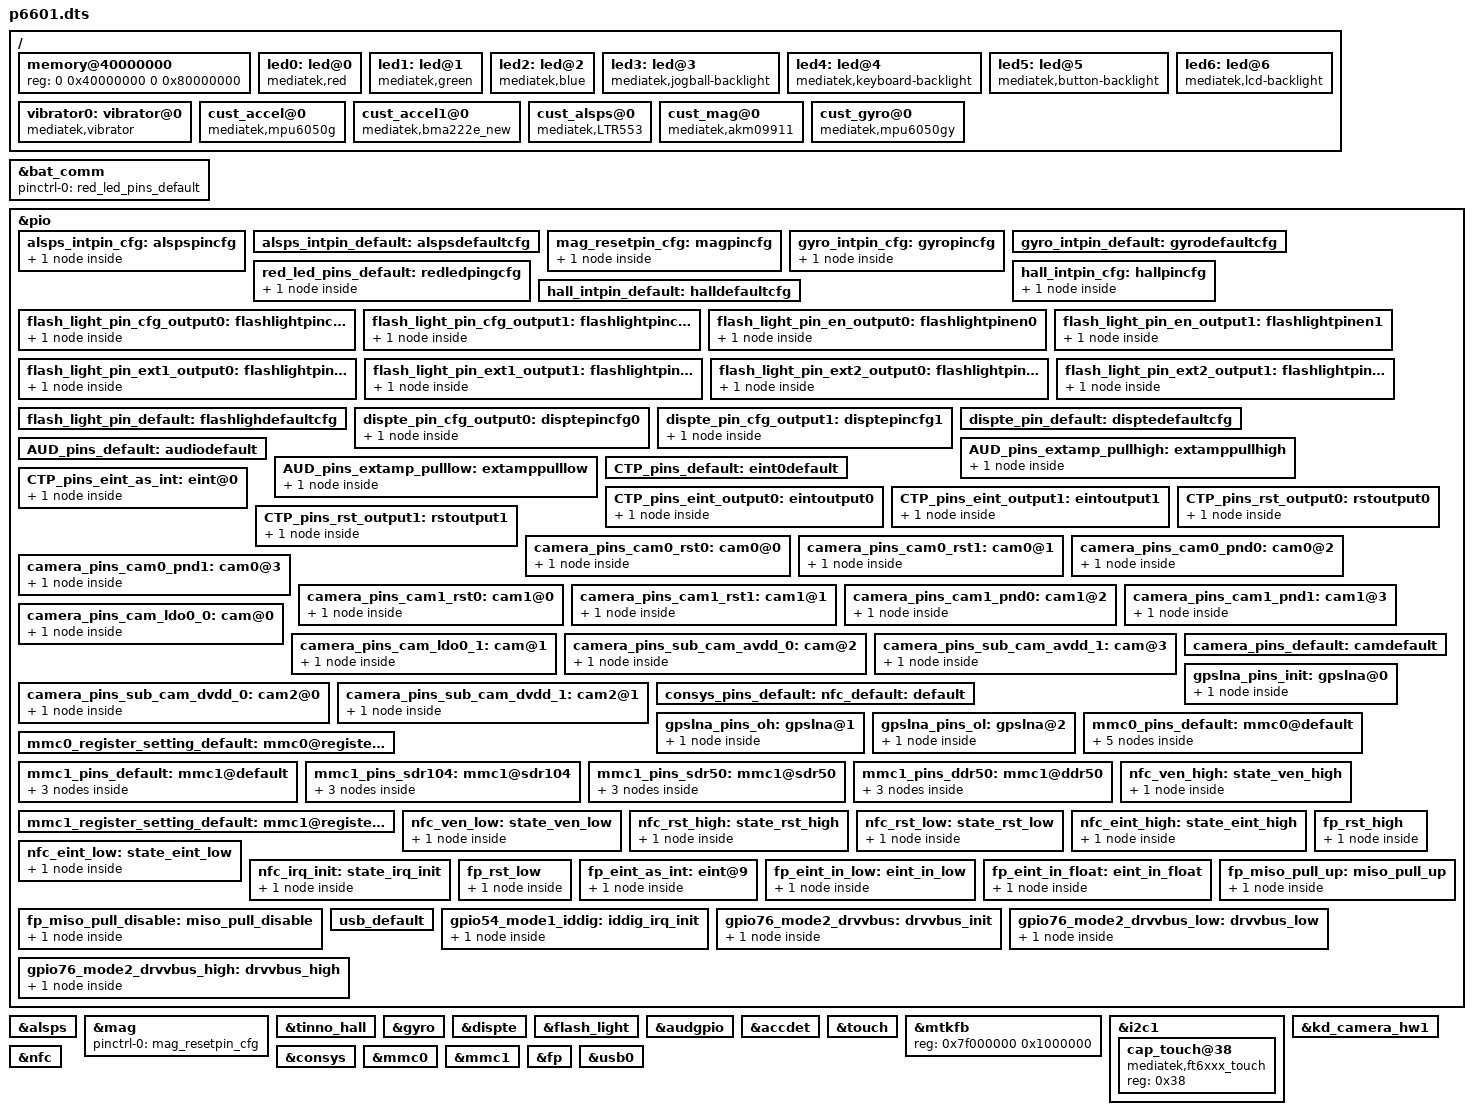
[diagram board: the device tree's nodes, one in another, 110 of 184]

/dts-v1/;

#include "mt6735.dtsi"
#include "cust.dtsi"

/ {
	memory@40000000 {
		device_type = "memory";
		reg = <0 0x40000000 0 0x80000000>;
	};

	led0:led@0 {
		compatible = "mediatek,red";
		led_mode = <3>;
		data = <2>;
		pwm_config = <0 0 0 0 0>;
	};
	led1:led@1 {
		compatible = "mediatek,green";
		led_mode = <3>;
		data = <1>;
		pwm_config = <0 0 0 0 0>;
	};
	led2:led@2 {
		compatible = "mediatek,blue";
		led_mode = <0>;
		data = <1>;
		pwm_config = <0 0 0 0 0>;
	};
	led3:led@3 {
		compatible = "mediatek,jogball-backlight";
		led_mode = <0>;
		data = <1>;
		pwm_config = <0 0 0 0 0>;
	};
	led4:led@4 {
		compatible = "mediatek,keyboard-backlight";
		led_mode = <0>;
		data = <1>;
		pwm_config = <0 0 0 0 0>;
	};
	led5:led@5 {
		compatible = "mediatek,button-backlight";
		led_mode = <0>;
		data = <1>;
		pwm_config = <0 0 0 0 0>;
	};
	led6:led@6 {
		compatible = "mediatek,lcd-backlight";
		led_mode = <5>;
		data = <1>;
		pwm_config = <0 0 0 0 0>;
	};
	vibrator0:vibrator@0 {
		compatible = "mediatek,vibrator";
		vib_timer = <25>;
		vib_limit = <9>;
		vib_vol= <5>;
	};
 /* sensor standardization */
		cust_accel@0 {
		compatible				= "mediatek,mpu6050g";
		i2c_num				= <2>;
		i2c_addr				= <0x68 0 0 0>;
		direction				= <6>;
		power_id				= <0xffff>;
		power_vol				= <0>;
		firlen					= <0>;
		is_batch_supported			= <0>;
		};
                //BEGIN <bma222e> <DATA20160309> <bma222e config> limi.zhang
		cust_accel1@0 {
		compatible				= "mediatek,bma222e_new";
		i2c_num				= <2>;
		i2c_addr				= <0x18 0 0 0>;
		direction				= <7>;
		power_id				= <0xffff>;
		power_vol				= <0>;
		firlen					= <0>;
		is_batch_supported			= <0>;
		};
                //END <bma222e> <DATA20160309> <bma222e config> limi.zhang
		cust_alsps@0 {
		compatible				= "mediatek,LTR553";
		i2c_num					= <2>;
		i2c_addr				= <0x23 0 0 0>;
		polling_mode_ps			= <0>;
		polling_mode_als		= <1>;
		power_id				= <0xffff>;
		power_vol				= <0>;
/* Total has 15 level*/
		als_level	= <2 16 32 64 613 1400 2238 3253 4401 5606 6844 8196 65535 65535 65535>;
/*  Total has 16 range*/
		als_value	= <18 50 95 190 1000 1700 1920 2900 5745 8500 10243 10243 10243 10243 10243 10243>;
		ps_threshold_high		=  <0x167>;
		ps_threshold_low		=  <0x74>;
		is_batch_supported_ps	= <0>;
		is_batch_supported_als	= <0>;
		};
		cust_mag@0 {
		compatible				= "mediatek,akm09911";
		i2c_num				= <2>;
		i2c_addr				= <0x0C 0 0 0>;
		direction				= <6>;
		power_id				= <0xffff>;
		power_vol				= <0>;
		is_batch_supported	= <0>;
		};

		cust_gyro@0 {
		compatible				= "mediatek,mpu6050gy";
		i2c_num				= <2>;
		i2c_addr				= <0x69 0 0 0>;
		direction				= <6>;
		power_id				= <0xffff>;
		power_vol				= <0>;
		firlen					= <0>;
		is_batch_supported	= <0>;
		};
};

&bat_comm {
	pinctrl-names = "default";
	pinctrl-0 = <&red_led_pins_default>;
};
/* sensor gpio standization */
&pio {
	alsps_intpin_cfg: alspspincfg {

	    pins_cmd_dat {
			pins = <PINMUX_GPIO58__FUNC_GPIO58>;
			slew-rate = <0>;
			bias-pull-up = <00>;
		};
	};

	alsps_intpin_default: alspsdefaultcfg {

	};

	mag_resetpin_cfg: magpincfg {
	    pins_cmd_dat {
			pins = <PINMUX_GPIO61__FUNC_GPIO61>;
			slew-rate = <1>;
			output-high;
		};
	};

	gyro_intpin_cfg: gyropincfg {

	    pins_cmd_dat {
			pins = <PINMUX_GPIO59__FUNC_GPIO59>;
			slew-rate = <0>;
			bias-pull-down = <00>;
		};
	};

	gyro_intpin_default: gyrodefaultcfg {

	};

	red_led_pins_default: redledpingcfg{
		pins_cmd_dat {
			pins = <PINMUX_GPIO8__FUNC_GPIO8>;
			slew-rate = <1>;
			output-high;
		};
	};


};
&alsps {
	pinctrl-names = "pin_default", "pin_cfg";
	pinctrl-0 = <&alsps_intpin_default>;
	pinctrl-1 = <&alsps_intpin_cfg>;
	status = "okay";

};

&mag {
	pinctrl-names = "default";
	pinctrl-0 = <&mag_resetpin_cfg>;
	status = "okay";
};

&pio {
	hall_intpin_cfg: hallpincfg {
	    pins_cmd_dat {
			pins = <PINMUX_GPIO0__FUNC_GPIO0>;
			slew-rate = <0>;
			bias-pull-up = <00>;
		};
	};
	hall_intpin_default: halldefaultcfg {
	};

};
&tinno_hall {
	pinctrl-names = "pin_default", "pin_cfg";
	pinctrl-0 = <&hall_intpin_default>;
	pinctrl-1 = <&hall_intpin_cfg>;
	status = "okay";
};

&gyro {
	pinctrl-names = "pin_default", "pin_cfg";
	pinctrl-0 = <&gyro_intpin_default>;
	pinctrl-1 = <&gyro_intpin_cfg>;
	status = "okay";

};
/* sensor end */
&pio {
	flash_light_pin_cfg_output0: flashlightpincfg0 {
	    pins_cmd_dat {
			pins = <PINMUX_GPIO42__FUNC_GPIO42>;
			slew-rate = <1>;
			output-low;
		};
	};
	flash_light_pin_cfg_output1: flashlightpincfg1 {
	    pins_cmd_dat {
			pins = <PINMUX_GPIO42__FUNC_GPIO42>;
			slew-rate = <1>;
			output-high;
		};
	};
	flash_light_pin_en_output0: flashlightpinen0 {
	    pins_cmd_dat {
			pins = <PINMUX_GPIO43__FUNC_GPIO43>;
			slew-rate = <1>;
			output-low;
		};
	};
	flash_light_pin_en_output1: flashlightpinen1 {
	    pins_cmd_dat {
			pins = <PINMUX_GPIO43__FUNC_GPIO43>;
			slew-rate = <1>;
			output-high;
		};
	};
	flash_light_pin_ext1_output0: flashlightpinext10 {
	    pins_cmd_dat {
			pins = <PINMUX_GPIO3__FUNC_GPIO3>;
			slew-rate = <1>;
			output-low;
		};
	};
	flash_light_pin_ext1_output1: flashlightpinext11 {
	    pins_cmd_dat {
			pins = <PINMUX_GPIO3__FUNC_GPIO3>;
			slew-rate = <1>;
			output-high;
		};
	};
	flash_light_pin_ext2_output0: flashlightpinext20 {
	    pins_cmd_dat {
			pins = <PINMUX_GPIO4__FUNC_GPIO4>;
			slew-rate = <1>;
			output-low;
		};
	};
	flash_light_pin_ext2_output1: flashlightpinext21 {
	    pins_cmd_dat {
			pins = <PINMUX_GPIO4__FUNC_GPIO4>;
			slew-rate = <1>;
			output-high;
		};
	};
	flash_light_pin_default: flashlighdefaultcfg {
	};

};
/*DISPTE START*/
&pio {
	dispte_pin_cfg_output0: disptepincfg0 {
	    pins_cmd_dat {
			pins = <PINMUX_GPIO146__FUNC_GPIO146>;
			slew-rate = <1>;
			output-low;
		};
	};
	dispte_pin_cfg_output1: disptepincfg1 {
	    pins_cmd_dat {
			pins = <PINMUX_GPIO146__FUNC_GPIO146>;
			slew-rate = <1>;
			output-high;
		};
	};
	dispte_pin_default: disptedefaultcfg {
	};
};
&dispte {
	pinctrl-names = "disptepin_default", "disptepin_cfg0", "disptepin_cfg1";
	pinctrl-0 = <&dispte_pin_default>;
	pinctrl-1 = <&dispte_pin_cfg_output0>;
	pinctrl-2 = <&dispte_pin_cfg_output1>;
	status = "okay";
};
/*DISPTE END*/
&flash_light {
	pinctrl-names = "flashlightpin_default", "flashlightpin_cfg0", "flashlightpin_cfg1","flashlightpin_en0","flashlightpin_en1"
			 ,"flashlightpin_ext10","flashlightpin_ext11","flashlightpin_ext20","flashlightpin_ext21";
	pinctrl-0 = <&flash_light_pin_default>;
	pinctrl-1 = <&flash_light_pin_cfg_output0>;
	pinctrl-2 = <&flash_light_pin_cfg_output1>;
	pinctrl-3 = <&flash_light_pin_en_output0>;
	pinctrl-4 = <&flash_light_pin_en_output1>;
	pinctrl-5 = <&flash_light_pin_ext1_output0>;
	pinctrl-6 = <&flash_light_pin_ext1_output1>;
	pinctrl-7 = <&flash_light_pin_ext2_output0>;
	pinctrl-8 = <&flash_light_pin_ext2_output1>;
	status = "okay";
};
/* AUDIO GPIO standardization */
&audgpio {
	pinctrl-names = "default", "extamp-pullhigh", "extamp-pulllow";
	pinctrl-0 = <&AUD_pins_default>;

	pinctrl-1 = <&AUD_pins_extamp_pullhigh>;
	pinctrl-2 = <&AUD_pins_extamp_pulllow>;
	gpio_extspkamp = <&pio 19 0>;//yangliang add for ext pa mode-2;
	status = "okay";
};
&pio {
	AUD_pins_default: audiodefault {
	};

	AUD_pins_extamp_pullhigh: extamppullhigh {
	    pins_cmd_dat {
			pins = <PINMUX_GPIO19__FUNC_GPIO19>;/*GPIO_extamp_PIN*/
			slew-rate = <1>;
			output-high;
		};
	};
	AUD_pins_extamp_pulllow: extamppulllow {
	    pins_cmd_dat {
			pins = <PINMUX_GPIO19__FUNC_GPIO19>;/*GPIO_extamp_PIN*/
			slew-rate = <1>;
			output-low;
		};
	};
};
/* AUDIO end */
&accdet {
		accdet-mic-vol = <7>;
		//headset-mode-setting = <0x500 0x200 1 0x1F0 0x800 0x800 0x20>;//yangliang mask and add for insert hph-pop according to mtk20160418
		headset-mode-setting = <0x500 0x500 1 0x3F0 0x800 0x800 0x20>; 
		accdet-plugout-debounce = <20>;
		/*1:ACC mode, 2:low cost without in bias, 6:low cost with in bias*/
		accdet-mic-mode = <6>;
		/*0--MD_MAX--UP_MAX--DW_MAX*/
		headset-three-key-threshold = <0 80 220 500>;
		/*0--MD_MAX--VOICE_MAX--UP_MAX--DW_MAX*/
		headset-four-key-threshold = <0 58 121 192 450>;
};
&touch {
	tpd-resolution = <720 1280>;
	use-tpd-button = <0>;
	tpd-key-num = <3>;
	tpd-key-local= <139 172 158 0>;
	tpd-key-dim-local = <90 883 100 40 230 883 100 40 370 883 100 40 0 0 0 0>;
	tpd-max-touch-num = <5>;
	tpd-filter-enable = <0>;
	tpd-filter-pixel-density = <124>;
	tpd-filter-custom-prameters = <0 0 0 0 0 0 0 0 0 0 0 0>;
	tpd-filter-custom-speed = <0 0 0>;
	pinctrl-names = "default", "state_eint_as_int", "state_eint_output0", "state_eint_output1",
		"state_rst_output0", "state_rst_output1";
	pinctrl-0 = <&CTP_pins_default>;
	pinctrl-1 = <&CTP_pins_eint_as_int>;
	pinctrl-2 = <&CTP_pins_eint_output0>;
	pinctrl-3 = <&CTP_pins_eint_output1>;
	pinctrl-4 = <&CTP_pins_rst_output0>;
	pinctrl-5 = <&CTP_pins_rst_output1>;
	status = "okay";
};

&mtkfb {
	reg = <0x7f000000 0x1000000>;
};


&pio {
	CTP_pins_default: eint0default {
	};
	CTP_pins_eint_as_int: eint@0 {
		pins_cmd_dat {
			pins = <PINMUX_GPIO10__FUNC_GPIO10>;
			slew-rate = <0>;
			bias-disable;
		};
	};
	CTP_pins_eint_output0: eintoutput0 {
		pins_cmd_dat {
			pins = <PINMUX_GPIO10__FUNC_GPIO10>;
			slew-rate = <1>;
			output-low;
		};
	};
	CTP_pins_eint_output1: eintoutput1 {
		pins_cmd_dat {
			pins = <PINMUX_GPIO10__FUNC_GPIO10>;
			slew-rate = <1>;
			output-high;
		};
	};
	CTP_pins_rst_output0: rstoutput0 {
		pins_cmd_dat {
			pins = <PINMUX_GPIO62__FUNC_GPIO62>;
			slew-rate = <1>;
			output-low;
		};
	};
	CTP_pins_rst_output1: rstoutput1 {
		pins_cmd_dat {
			pins = <PINMUX_GPIO62__FUNC_GPIO62>;
			slew-rate = <1>;
			output-high;
		};
	};
};
/* TOUCH end */
&i2c1 {
	cap_touch@38 {
		compatible = "mediatek,ft6xxx_touch";
		reg = <0x38>;
		status = "okay";
	};

};
/* CAMERA GPIO standardization */
&pio {
	camera_pins_cam0_rst0: cam0@0 {
		pins_cmd_dat {
			pins = <PINMUX_GPIO44__FUNC_GPIO44>;/*GPIO_CAMERA_CMRST_PIN*/
			slew-rate = <1>; /*direction 0:in, 1:out*/
			output-low;/*direction out used only. output_low or high*/
		};
	};
	camera_pins_cam0_rst1: cam0@1 {
		pins_cmd_dat {
			pins = <PINMUX_GPIO44__FUNC_GPIO44>;/*GPIO_CAMERA_CMRST_PIN*/
			slew-rate = <1>;
			output-high;
		};
	};
	camera_pins_cam0_pnd0: cam0@2 {
		pins_cmd_dat {
			pins = <PINMUX_GPIO7__FUNC_GPIO7>;/*GPIO_CAMERA_CMPDN_PIN*/
			slew-rate = <1>;
			output-low;
		};
	};
	camera_pins_cam0_pnd1: cam0@3 {
		pins_cmd_dat {
			pins = <PINMUX_GPIO7__FUNC_GPIO7>;/*GPIO_CAMERA_CMPDN_PIN*/
			slew-rate = <1>;
			output-high;
		};
	};
	camera_pins_cam1_rst0: cam1@0 {
		pins_cmd_dat {
			pins = <PINMUX_GPIO11__FUNC_GPIO11>;/*GPIO_CAMERA_CMRST1_PIN*/
			slew-rate = <1>; /*direction 0:in, 1:out*/
			output-low;/*direction out used only. output_low or high*/
		};
	};
	camera_pins_cam1_rst1: cam1@1 {
		pins_cmd_dat {
			pins = <PINMUX_GPIO11__FUNC_GPIO11>;/*GPIO_CAMERA_CMRST1_PIN*/
			slew-rate = <1>;
			output-high;
		};
	};
	camera_pins_cam1_pnd0: cam1@2 {
		pins_cmd_dat {
			pins = <PINMUX_GPIO12__FUNC_GPIO12>;/*GPIO_CAMERA_CMPDN1_PIN*/
			slew-rate = <1>;
			output-low;
		};
	};
	camera_pins_cam1_pnd1: cam1@3 {
		pins_cmd_dat {
			pins = <PINMUX_GPIO12__FUNC_GPIO12>;/*GPIO_CAMERA_CMPDN1_PIN*/
			slew-rate = <1>;
			output-high;
		};
	};
	camera_pins_cam_ldo0_0: cam@0 {
		pins_cmd_dat {
			pins = <PINMUX_GPIO83__FUNC_GPIO83>;
			slew-rate = <1>;
			output-low;
		};
	};
	camera_pins_cam_ldo0_1: cam@1 {
		pins_cmd_dat {
			pins = <PINMUX_GPIO83__FUNC_GPIO83>;
			slew-rate = <1>;
			output-high;
		};
	};
	camera_pins_sub_cam_avdd_0: cam@2 {
		pins_cmd_dat {
			pins = <PINMUX_GPIO78__FUNC_GPIO78>;
			slew-rate = <1>;
			output-low;
		};
	};
	camera_pins_sub_cam_avdd_1: cam@3 {
		pins_cmd_dat {
			pins = <PINMUX_GPIO78__FUNC_GPIO78>;
			slew-rate = <1>;
			output-high;
		};
	};
	camera_pins_sub_cam_dvdd_0: cam2@0 {
		pins_cmd_dat {
			pins = <PINMUX_GPIO80__FUNC_GPIO80>;
			slew-rate = <1>;
			output-low;
		};
	};
	camera_pins_sub_cam_dvdd_1: cam2@1 {
		pins_cmd_dat {
			pins = <PINMUX_GPIO80__FUNC_GPIO80>;
			slew-rate = <1>;
			output-high;
		};
	};
	camera_pins_default: camdefault {

	};
};

&kd_camera_hw1 {
	pinctrl-names = "default", "cam0_rst0", "cam0_rst1", "cam0_pnd0", "cam0_pnd1",
	"cam1_rst0", "cam1_rst1", "cam1_pnd0", "cam1_pnd1",
	"cam_ldo0_0", "cam_ldo0_1","sub_cam_avdd_0","sub_cam_avdd_1","sub_cam_dvdd_0","sub_cam_dvdd_1";
	pinctrl-0 = <&camera_pins_default>;
	pinctrl-1 = <&camera_pins_cam0_rst0>;
	pinctrl-2 = <&camera_pins_cam0_rst1>;
	pinctrl-3 = <&camera_pins_cam0_pnd0>;
	pinctrl-4 = <&camera_pins_cam0_pnd1>;
	pinctrl-5 = <&camera_pins_cam1_rst0>;
	pinctrl-6 = <&camera_pins_cam1_rst1>;
	pinctrl-7 = <&camera_pins_cam1_pnd0>;
	pinctrl-8 = <&camera_pins_cam1_pnd1>;
	pinctrl-9 = <&camera_pins_cam_ldo0_0>;
	pinctrl-10 = <&camera_pins_cam_ldo0_1>;
	pinctrl-11 = <&camera_pins_sub_cam_avdd_0>;
	pinctrl-12 = <&camera_pins_sub_cam_avdd_1>;
	pinctrl-13 = <&camera_pins_sub_cam_dvdd_0>;
	pinctrl-14 = <&camera_pins_sub_cam_dvdd_1>;
	status = "okay";

};
/* CAMERA GPIO end */

/* CONSYS GPIO standardization */
&pio {
	consys_pins_default: default {

	};

	gpslna_pins_init: gpslna@0 {

	    pins_cmd_dat {
			pins = <PINMUX_GPIO79__FUNC_GPIO79>;
			slew-rate = <0>;
			bias-disable;
			output-low;
		};
	};

	gpslna_pins_oh: gpslna@1 {

	    pins_cmd_dat {
			pins = <PINMUX_GPIO79__FUNC_GPIO79>;
			slew-rate = <1>;
			output-high;
		};
	};

	gpslna_pins_ol: gpslna@2 {

	    pins_cmd_dat {
			pins = <PINMUX_GPIO79__FUNC_GPIO79>;
			slew-rate = <1>;
			output-low;
		};
	};

};

&consys {
	pinctrl-names = "default", "gps_lna_state_init", "gps_lna_state_oh", "gps_lna_state_ol";
	pinctrl-0 = <&consys_pins_default>;
	pinctrl-1 = <&gpslna_pins_init>;
	pinctrl-2 = <&gpslna_pins_oh>;
	pinctrl-3 = <&gpslna_pins_ol>;
	status = "okay";

};
/* CONSYS end */

/* mmc start */
&mmc0 {
		clk_src = /bits/ 8 <MSDC50_CLKSRC_400MHZ>;
		bus-width = <8>;
		max-frequency = <200000000>;
		cap-mmc-highspeed;
		msdc-sys-suspend;
		mmc-ddr-1_8v;
		mmc-hs200-1_8v;
		mmc-hs400-1_8v;
		non-removable;
		pinctl = <&mmc0_pins_default>;
		register_setting = <&mmc0_register_setting_default>;
		host_function = /bits/ 8 <MSDC_EMMC>;
		bootable;
		status = "okay";
};

&mmc1 {
		clk_src = /bits/ 8 <MSDC30_CLKSRC_200MHZ>;
		bus-width = <4>;
		max-frequency = <200000000>;
		msdc-sys-suspend;
		cap-sd-highspeed;
		sd-uhs-sdr12;
		sd-uhs-sdr25;
		sd-uhs-sdr50;
		sd-uhs-sdr104;
		sd-uhs-ddr50;
		pinctl = <&mmc1_pins_default>;
		pinctl_sdr104 = <&mmc1_pins_sdr104>;
		pinctl_sdr50 = <&mmc1_pins_sdr50>;
		pinctl_ddr50 = <&mmc1_pins_ddr50>;
		register_setting = <&mmc1_register_setting_default>;
		host_function = /bits/ 8 <MSDC_SD>;
		cd_level = /bits/ 8 <MSDC_CD_LOW>;
		cd-gpios = <&pio 5 0>;
		status = "okay";
};

&pio {
	mmc0_pins_default: mmc0@default {
			pins_cmd {
				drive-strength = /bits/ 8 <2>;
			};
			pins_dat {
				drive-strength = /bits/ 8 <2>;
			};
			pins_clk {
				drive-strength = /bits/ 8 <2>;
			};
			pins_rst {
				drive-strength = /bits/ 8 <2>;
			};
			pins_ds {
				drive-strength = /bits/ 8 <2>;
			};
	};

	mmc0_register_setting_default: mmc0@register_default {
		dat0rddly      = /bits/ 8 <0>;
		dat1rddly      = /bits/ 8 <0>;
		dat2rddly      = /bits/ 8 <0>;
		dat3rddly      = /bits/ 8 <0>;
		dat4rddly      = /bits/ 8 <0>;
		dat5rddly      = /bits/ 8 <0>;
		dat6rddly      = /bits/ 8 <0>;
		dat7rddly      = /bits/ 8 <0>;
		datwrddly      = /bits/ 8 <0>;
		cmdrrddly      = /bits/ 8 <0>;
		cmdrddly       = /bits/ 8 <0>;
		cmd_edge = /bits/ 8 <MSDC_SMPL_FALLING>;
		rdata_edge = /bits/ 8 <MSDC_SMPL_FALLING>;
		wdata_edge = /bits/ 8 <MSDC_SMPL_FALLING>;

		ett-hs200-cells = <12>;
		ett-hs200-default = <OFFSET_MSDC_PATCH_BIT0	MSDC_PB0_INT_DAT_LATCH_CK_SEL 0x0
			OFFSET_MSDC_PATCH_BIT0	MSDC_PB0_CKGEN_MSDC_DLY_SEL   0x0
			OFFSET_MSDC_PATCH_BIT1	MSDC_PB1_CMD_RSP_TA_CNTR      0x1
			OFFSET_MSDC_IOCON		MSDC_IOCON_RSPL               0x0
			OFFSET_MSDC_PAD_TUNE0	MSDC_PAD_TUNE0_CMDRDLY        0x7
			OFFSET_MSDC_PAD_TUNE0	MSDC_PAD_TUNE0_CMDRRDLY       0xb
			OFFSET_MSDC_PATCH_BIT1		MSDC_PB1_WRDAT_CRCS_TA_CNTR   0x1
			OFFSET_MSDC_PAD_TUNE0	MSDC_PAD_TUNE0_DATWRDLY       0xb
			OFFSET_MSDC_IOCON			MSDC_IOCON_W_D0SPL            0x0
			OFFSET_MSDC_DAT_RDDLY0		MSDC_DAT_RDDLY0_D0            0x7
			OFFSET_MSDC_PAD_TUNE0	MSDC_PAD_TUNE0_DATRRDLY       0x9
			OFFSET_MSDC_IOCON		MSDC_IOCON_R_D_SMPL           0x0>;

		ett-hs400-cells = <8>;
		ett-hs400-default = <OFFSET_MSDC_PATCH_BIT0	MSDC_PB0_INT_DAT_LATCH_CK_SEL	0x0
			OFFSET_MSDC_PATCH_BIT0		MSDC_PB0_CKGEN_MSDC_DLY_SEL		0x0
			OFFSET_EMMC50_PAD_DS_TUNE	MSDC_EMMC50_PAD_DS_TUNE_DLY1	0x2
			OFFSET_EMMC50_PAD_DS_TUNE	MSDC_EMMC50_PAD_DS_TUNE_DLY3	0x10
			OFFSET_MSDC_PATCH_BIT1			MSDC_PB1_CMD_RSP_TA_CNTR	0x1
			OFFSET_MSDC_IOCON		MSDC_IOCON_RSPL				0x0
			OFFSET_MSDC_PAD_TUNE0			MSDC_PAD_TUNE0_CMDRDLY		0x6
			OFFSET_MSDC_PAD_TUNE0		MSDC_PAD_TUNE0_CMDRRDLY		0x6>;
	};

	mmc1_pins_default: mmc1@default {
			pins_cmd {
				drive-strength = /bits/ 8 <3>;
			};
			pins_dat {
				drive-strength = /bits/ 8 <3>;
			};
			pins_clk {
				drive-strength = /bits/ 8 <3>;
			};
	};

	mmc1_pins_sdr104: mmc1@sdr104 {
			pins_cmd {
				drive-strength = /bits/ 8 <2>;
			};
			pins_dat {
				drive-strength = /bits/ 8 <2>;
			};
			pins_clk {
				drive-strength = /bits/ 8 <3>;
			};
	};

	mmc1_pins_sdr50: mmc1@sdr50 {
			pins_cmd {
				drive-strength = /bits/ 8 <2>;
			};
			pins_dat {
				drive-strength = /bits/ 8 <2>;
			};
			pins_clk {
				drive-strength = /bits/ 8 <3>;
			};
	};

	mmc1_pins_ddr50: mmc1@ddr50 {
			pins_cmd {
				drive-strength = /bits/ 8 <2>;
			};
			pins_dat {
				drive-strength = /bits/ 8 <2>;
			};
			pins_clk {
				drive-strength = /bits/ 8 <3>;
			};
	};

	mmc1_register_setting_default: mmc1@register_default {
				dat0rddly      = /bits/ 8 <0>;
				dat1rddly      = /bits/ 8 <0>;
				dat2rddly      = /bits/ 8 <0>;
				dat3rddly      = /bits/ 8 <0>;
				datwrddly      = /bits/ 8 <0>;
				cmdrrddly      = /bits/ 8 <0>;
				cmdrddly       = /bits/ 8 <0>;
				cmd_edge = /bits/ 8 <MSDC_SMPL_FALLING>;
				rdata_edge = /bits/ 8 <MSDC_SMPL_FALLING>;
				wdata_edge = /bits/ 8 <MSDC_SMPL_FALLING>;
	};
};
/* mmc end */

/* NFC GPIO standardization */
&pio {
	nfc_default: default {

	};

	nfc_ven_high: state_ven_high {
		pins_cmd_dat {
			pins = <PINMUX_GPIO4__FUNC_GPIO4>;
			slew-rate = <1>;
			output-high;
		};
	};

	nfc_ven_low: state_ven_low {
		pins_cmd_dat {
			pins = <PINMUX_GPIO4__FUNC_GPIO4>;
			slew-rate = <1>;
			output-low;
		};
	};

	nfc_rst_high: state_rst_high {
		pins_cmd_dat {
			pins = <PINMUX_GPIO3__FUNC_GPIO3>;
			slew-rate = <1>;
			output-high;
		};
	};

	nfc_rst_low: state_rst_low {
		pins_cmd_dat {
			pins = <PINMUX_GPIO3__FUNC_GPIO3>;
			slew-rate = <1>;
			output-low;
		};
	};

	nfc_eint_high: state_eint_high {
		pins_cmd_dat {
			pins = <PINMUX_GPIO1__FUNC_GPIO1>;
			slew-rate = <1>;
			output-high;
		};
	};

	nfc_eint_low: state_eint_low {
		pins_cmd_dat {
			pins = <PINMUX_GPIO1__FUNC_GPIO1>;
			slew-rate = <1>;
			output-low;
		};
	};

	nfc_irq_init: state_irq_init {
		pins_cmd_dat {
			pins = <PINMUX_GPIO2__FUNC_GPIO2>;
			slew-rate = <0>;
			bias-pull-down = <00>;
		};
	};
};

&nfc {
	pinctrl-names = "default", "ven_high", "ven_low", "rst_high", "rst_low", "eint_high", "eint_low", "irq_init";
	pinctrl-0 = <&nfc_default>;
	pinctrl-1 = <&nfc_ven_high>;
	pinctrl-2 = <&nfc_ven_low>;
	pinctrl-3 = <&nfc_rst_high>;
	pinctrl-4 = <&nfc_rst_low>;
	pinctrl-5 = <&nfc_eint_high>;
	pinctrl-6 = <&nfc_eint_low>;
	pinctrl-7 = <&nfc_irq_init>;
	status = "okay";
};
/* NFC end */

/* Fingerprint GPIO standardization */
&pio {
	fp_default: default {
	};

	fp_rst_high: fp_rst_high {
		pins_cmd_dat {
			pins = <PINMUX_GPIO20__FUNC_GPIO20>;
			slew-rate = <1>;
			output-high;
		};
	};

	fp_rst_low: fp_rst_low {
		pins_cmd_dat {
			pins = <PINMUX_GPIO20__FUNC_GPIO20>;
			slew-rate = <1>;
			output-low;
		};
	};


	fp_eint_as_int: eint@9 {
		pins_cmd_dat {
			pins = <PINMUX_GPIO9__FUNC_GPIO9>;
			slew-rate = <0>;
			bias-disable;
		};
	};
	fp_eint_in_low: eint_in_low {
		pins_cmd_dat {
			pins = <PINMUX_GPIO9__FUNC_GPIO9>;
			slew-rate = <0>;
			bias-pull-down = <00>;
		};
	};
	fp_eint_in_float: eint_in_float {
		pins_cmd_dat {
			pins = <PINMUX_GPIO9__FUNC_GPIO9>;
			slew-rate = <0>;
			bias-disable;
		};
	};
	fp_miso_pull_up: miso_pull_up {
		pins_cmd_dat {
			pins = <PINMUX_GPIO67__FUNC_GPIO67>;
			slew-rate = <0>;
			bias-pull-up = <00>;
		};
	};
	fp_miso_pull_disable: miso_pull_disable {
		pins_cmd_dat {
			pins = <PINMUX_GPIO67__FUNC_SPI_MIA>;
			bias-disable;
		};
	};
};

&fp {
	pinctrl-names = "fp_default", "fp_rst_high", "fp_rst_low","eint_as_int", "eint_in_low", "eint_in_float", "miso_pull_up", "miso_pull_disable";
	pinctrl-0 = <&fp_default>;
	pinctrl-1 = <&fp_rst_high>;
	pinctrl-2 = <&fp_rst_low>;
	pinctrl-3 = <&fp_eint_as_int>;
	pinctrl-4 = <&fp_eint_in_low>;
	pinctrl-5 = <&fp_eint_in_float>;
	pinctrl-6 = <&fp_miso_pull_up>;
	pinctrl-7 = <&fp_miso_pull_disable>;
	status = "okay";
};

/* Fingerprint end */

/* USB GPIO Kernal Standardization start */
&pio {
	usb_default: usb_default {
	};

	gpio54_mode1_iddig: iddig_irq_init {
		pins_cmd_dat {
			pins = <PINMUX_GPIO54__FUNC_IDDIG>;
			slew-rate = <0>;
			bias-pull-up = <00>;
		};
	};

	gpio76_mode2_drvvbus: drvvbus_init {
		pins_cmd_dat {
			pins = <PINMUX_GPIO76__FUNC_GPIO76>;
			slew-rate = <1>;
			bias-pull-up = <00>;
			output-low;
		};
	};

	gpio76_mode2_drvvbus_low: drvvbus_low {
		pins_cmd_dat {
			pins = <PINMUX_GPIO76__FUNC_GPIO76>;
			slew-rate = <1>;
			output-low;
		};
	};

	gpio76_mode2_drvvbus_high: drvvbus_high {
		pins_cmd_dat {
			pins = <PINMUX_GPIO76__FUNC_GPIO76>;
			slew-rate = <1>;
			output-high;
		};
	};
};

&usb0 {
	iddig_gpio = <54 3>;
	pinctrl-names = "usb_default", "iddig_irq_init", "drvvbus_init", "drvvbus_low", "drvvbus_high";
	pinctrl-0 = <&usb_default>;
	pinctrl-1 = <&gpio54_mode1_iddig>;
	pinctrl-2 = <&gpio76_mode2_drvvbus>;
	pinctrl-3 = <&gpio76_mode2_drvvbus_low>;
	pinctrl-4 = <&gpio76_mode2_drvvbus_high>;
	status = "okay";
};
/* USB GPIO Kernal Standardization end */
